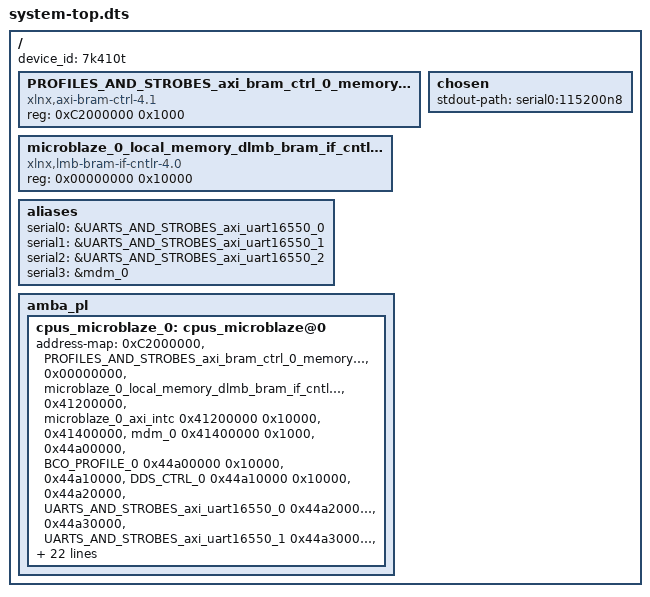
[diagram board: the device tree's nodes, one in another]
/dts-v1/;
#include "pl.dtsi"
/ {
	device_id = "7k410t";
	#address-cells = <1>;
	#size-cells = <1>;
	PROFILES_AND_STROBES_axi_bram_ctrl_0_memory: memory@c2000000 {
		compatible = "xlnx,axi-bram-ctrl-4.1";
		device_type = "memory";
		reg = <0xC2000000 0x1000>;
	};
	microblaze_0_local_memory_dlmb_bram_if_cntlr_memory: memory@0 {
		compatible = "xlnx,lmb-bram-if-cntlr-4.0";
		device_type = "memory";
		reg = <0x00000000 0x10000>;
	};
	chosen {
		stdout-path = "serial0:115200n8";
	};
	aliases {
		serial0 = &UARTS_AND_STROBES_axi_uart16550_0;
		serial1 = &UARTS_AND_STROBES_axi_uart16550_1;
		serial2 = &UARTS_AND_STROBES_axi_uart16550_2;
		serial3 = &mdm_0;
	};
	amba_pl: amba_pl {
		cpus_microblaze_0: cpus_microblaze@0 {
			address-map = <0xC2000000 &PROFILES_AND_STROBES_axi_bram_ctrl_0_memory 0xC2000000 0x1000>, 
			      <0x00000000 &microblaze_0_local_memory_dlmb_bram_if_cntlr_memory 0x00000000 0x10000>, 
			      <0x41200000 &microblaze_0_axi_intc 0x41200000 0x10000>, 
			      <0x41400000 &mdm_0 0x41400000 0x1000>, 
			      <0x44a00000 &BCO_PROFILE_0 0x44a00000 0x10000>, 
			      <0x44a10000 &DDS_CTRL_0 0x44a10000 0x10000>, 
			      <0x44a20000 &UARTS_AND_STROBES_axi_uart16550_0 0x44a20000 0x10000>, 
			      <0x44a30000 &UARTS_AND_STROBES_axi_uart16550_1 0x44a30000 0x10000>, 
			      <0x44a40000 &SVV_AXI_CYCCNT_0 0x44a40000 0x1000>, 
			      <0x44a50000 &UARTS_AND_STROBES_axi_uart16550_2 0x44a50000 0x10000>, 
			      <0x44a60000 &JESD204B_RX_CHAIN_1_axi_adxcvr_0 0x44a60000 0x10000>, 
			      <0x44a70000 &SVV_AXI_GPIO_0 0x44a70000 0x10000>, 
			      <0x44a80000 &SVV_AXI_ADI_SPI_LMK 0x44a80000 0x10000>, 
			      <0x44a90000 &SVV_AXI_ADI_SPI_ADC 0x44a90000 0x10000>, 
			      <0x44aa0000 &JESD204B_RX_CHAIN_1_axi_jesd204_rx_0 0x44aa0000 0x10000>, 
			      <0x44ab0000 &JESD204B_RX_CHAIN_1_ad_ip_jesd204_tpl_adc_0 0x44ab0000 0x10000>, 
			      <0x44ac0000 &JESD204B_RX_CHAIN_2_axi_adxcvr_1 0x44ac0000 0x10000>, 
			      <0x44ad0000 &JESD204B_RX_CHAIN_2_axi_jesd204_rx_1 0x44ad0000 0x10000>, 
			      <0x44ae0000 &JESD204B_RX_CHAIN_2_ad_ip_jesd204_tpl_adc_1 0x44ae0000 0x10000>;
			#ranges-address-cells = <0x1>;
			#ranges-size-cells = <0x1>;
		};
	};
};
